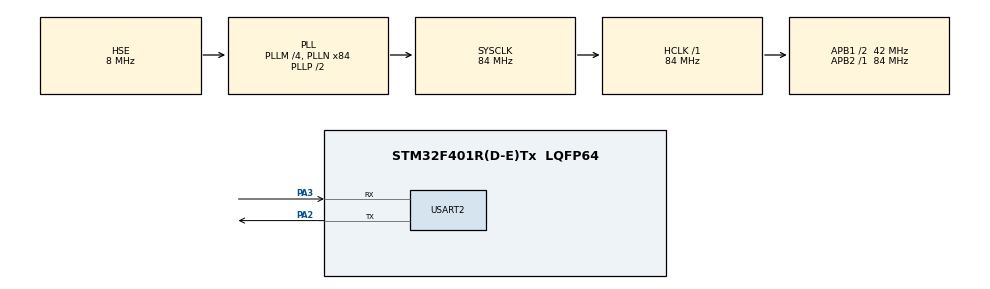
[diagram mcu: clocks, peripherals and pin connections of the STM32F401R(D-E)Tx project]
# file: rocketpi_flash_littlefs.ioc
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Mcu.Family=STM32F4
Mcu.Name=STM32F401R(D-E)Tx
Mcu.Package=LQFP64
NVIC.PriorityGroup=NVIC_PRIORITYGROUP_4
PA13.Mode=Serial_Wire
PA13.Signal=SYS_JTMS-SWDIO
PA14.Mode=Serial_Wire
PA14.Signal=SYS_JTCK-SWCLK
PA2.Mode=Asynchronous
PA2.Signal=USART2_TX
PA3.Mode=Asynchronous
PA3.Signal=USART2_RX
PH0\ -\ OSC_IN.Mode=HSE-External-Oscillator
PH0\ -\ OSC_IN.Signal=RCC_OSC_IN
PH1\ -\ OSC_OUT.Mode=HSE-External-Oscillator
PH1\ -\ OSC_OUT.Signal=RCC_OSC_OUT
ProjectManager.HeapSize=0x1000
ProjectManager.StackSize=0x1000
ProjectManager.TargetToolchain=MDK-ARM V5.27
RCC.48MHZClocksFreq_Value=42000000
RCC.AHBFreq_Value=84000000
RCC.APB1CLKDivider=RCC_HCLK_DIV2
RCC.APB1Freq_Value=42000000
RCC.APB1TimFreq_Value=84000000
RCC.APB2Freq_Value=84000000
RCC.APB2TimFreq_Value=84000000
RCC.CortexFreq_Value=84000000
RCC.HCLKFreq_Value=84000000
RCC.HSE_VALUE=8000000
RCC.HSI_VALUE=16000000
RCC.LSE_VALUE=32768
RCC.PLLM=4
RCC.PLLN=84
RCC.PLLSourceVirtual=RCC_PLLSOURCE_HSE
RCC.SYSCLKFreq_VALUE=84000000
RCC.SYSCLKSource=RCC_SYSCLKSOURCE_PLLCLK
RCC.VCOOutputFreq_Value=168000000
USART2.VirtualMode=VM_ASYNC
board=custom

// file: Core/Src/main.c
/* USER CODE BEGIN Header */
/**
  ******************************************************************************
  * @file           : main.c
  * @brief          : Main program body
  ******************************************************************************
  * @attention
  *
  * Copyright (c) 2025 STMicroelectronics.
  * All rights reserved.
  *
  * This software is licensed under terms that can be found in the LICENSE file
  * in the root directory of this software component.
  * If no LICENSE file comes with this software, it is provided AS-IS.
  *
  ******************************************************************************
  */
/* USER CODE END Header */
#include "main.h"
#include "usart.h"
#include "gpio.h"

/* USER CODE BEGIN Includes */
#include <stdio.h>
#include <string.h>

#include "lfs.h"
#include "lfs_port.h"
/* USER CODE END Includes */

/* USER CODE BEGIN PV */
static lfs_t g_lfs;
/* USER CODE END PV */

void SystemClock_Config(void);
/* USER CODE BEGIN PFP */
static void LittleFS_Test(void);
static void LittleFS_Log(const char *msg);
static void LittleFS_LogError(const char *msg, int err);
/* USER CODE END PFP */

/* USER CODE BEGIN 0 */
static void LittleFS_Log(const char *msg)
{
  if (msg == NULL) {
    return;
  }

  HAL_UART_Transmit(&huart2, (uint8_t *)msg, strlen(msg), HAL_MAX_DELAY);
}

static void LittleFS_LogError(const char *msg, int err)
{
  char buffer[96];
  int len = snprintf(buffer, sizeof(buffer),
                     "%s (err=%d)\r\n", msg, err);
  if ((len > 0) && (len < (int)sizeof(buffer))) {
    LittleFS_Log(buffer);
  }
}
/* USER CODE END 0 */

int main(void)
{

  /* MCU Configuration--------------------------------------------------------*/

  /* Reset of all peripherals, Initializes the Flash interface and the Systick. */
  HAL_Init();

  /* Configure the system clock */
  SystemClock_Config();

  /* Initialize all configured peripherals */
  MX_GPIO_Init();
  MX_USART2_UART_Init();
  /* USER CODE BEGIN 2 */
  LittleFS_Test();

  /* USER CODE END 2 */

  /* Infinite loop */
  while (1)
  {

  }
}

void SystemClock_Config(void)
{
  RCC_OscInitTypeDef RCC_OscInitStruct = {0};
  RCC_ClkInitTypeDef RCC_ClkInitStruct = {0};

  /** Configure the main internal regulator output voltage
  */
  __HAL_RCC_PWR_CLK_ENABLE();
  __HAL_PWR_VOLTAGESCALING_CONFIG(PWR_REGULATOR_VOLTAGE_SCALE2);

  /** Initializes the RCC Oscillators according to the specified parameters
  * in the RCC_OscInitTypeDef structure.
  */
  RCC_OscInitStruct.OscillatorType = RCC_OSCILLATORTYPE_HSE;
  RCC_OscInitStruct.HSEState = RCC_HSE_ON;
  RCC_OscInitStruct.PLL.PLLState = RCC_PLL_ON;
  RCC_OscInitStruct.PLL.PLLSource = RCC_PLLSOURCE_HSE;
  RCC_OscInitStruct.PLL.PLLM = 4;
  RCC_OscInitStruct.PLL.PLLN = 84;
  RCC_OscInitStruct.PLL.PLLP = RCC_PLLP_DIV2;
  RCC_OscInitStruct.PLL.PLLQ = 4;
  if (HAL_RCC_OscConfig(&RCC_OscInitStruct) != HAL_OK)
  {
    Error_Handler();
  }

  /** Initializes the CPU, AHB and APB buses clocks
  */
  RCC_ClkInitStruct.ClockType = RCC_CLOCKTYPE_HCLK|RCC_CLOCKTYPE_SYSCLK
                              |RCC_CLOCKTYPE_PCLK1|RCC_CLOCKTYPE_PCLK2;
  RCC_ClkInitStruct.SYSCLKSource = RCC_SYSCLKSOURCE_PLLCLK;
  RCC_ClkInitStruct.AHBCLKDivider = RCC_SYSCLK_DIV1;
  RCC_ClkInitStruct.APB1CLKDivider = RCC_HCLK_DIV2;
  RCC_ClkInitStruct.APB2CLKDivider = RCC_HCLK_DIV1;

  if (HAL_RCC_ClockConfig(&RCC_ClkInitStruct, FLASH_LATENCY_2) != HAL_OK)
  {
    Error_Handler();
  }
}

/* USER CODE BEGIN 4 */
static void LittleFS_Test(void)
{
  struct lfs_file file;
  char read_buffer[64] = {0};
  const char *path = "flash.txt";
  const char *payload = "LittleFS STM32F401 Flash Demo\r\n";

  int err = lfs_port_mount(&g_lfs);
  if (err != LFS_ERR_OK) {
    LittleFS_LogError("LittleFS: initial mount failed", err);
    LittleFS_Log("LittleFS: formatting flash...\r\n");
    err = lfs_port_format(&g_lfs);
    if (err == LFS_ERR_OK) {
      LittleFS_Log("LittleFS: format done\r\n");
      err = lfs_port_mount(&g_lfs);
    } else {
      LittleFS_LogError("LittleFS: format failed", err);
    }
  }

  if (err != LFS_ERR_OK) {
    LittleFS_LogError("LittleFS: mount failed", err);
    return;
  }

  err = lfs_file_open(&g_lfs, &file, path,
                      LFS_O_WRONLY | LFS_O_CREAT | LFS_O_TRUNC);
  if (err < 0) {
    LittleFS_LogError("LittleFS: open for write failed", err);
    lfs_port_unmount(&g_lfs);
    return;
  }

  lfs_ssize_t written = lfs_file_write(&g_lfs, &file, payload, strlen(payload));
  lfs_file_close(&g_lfs, &file);

  if (written < 0) {
    LittleFS_LogError("LittleFS: write failed", (int)written);
    lfs_port_unmount(&g_lfs);
    return;
  }

  err = lfs_file_open(&g_lfs, &file, path, LFS_O_RDONLY);
  if (err < 0) {
    LittleFS_LogError("LittleFS: open for read failed", err);
    lfs_port_unmount(&g_lfs);
    return;
  }

  lfs_ssize_t read = lfs_file_read(&g_lfs, &file, read_buffer,
                                   sizeof(read_buffer) - 1U);
  lfs_file_close(&g_lfs, &file);

  if (read < 0) {
    LittleFS_LogError("LittleFS: read failed", (int)read);
    lfs_port_unmount(&g_lfs);
    return;
  }

  read_buffer[read] = '\0';

  char log_buffer[128];
  int len = snprintf(log_buffer, sizeof(log_buffer),
                     "LittleFS OK (%ld bytes): %s\r\n",
                     (long)read, read_buffer);
  if ((len > 0) && (len < (int)sizeof(log_buffer))) {
    LittleFS_Log(log_buffer);
  }

  lfs_port_unmount(&g_lfs);
}
/* USER CODE END 4 */

void Error_Handler(void)
{
  __disable_irq();
  while (1)
  {
  }
}
